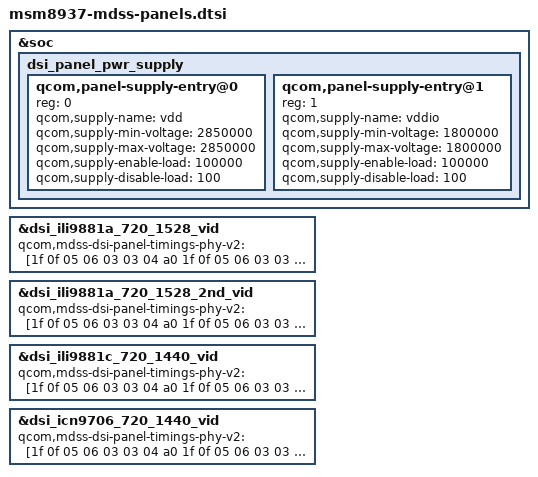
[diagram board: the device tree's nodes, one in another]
/* Copyright (c) 2015-2016, The Linux Foundation. All rights reserved.
 *
 * This program is free software; you can redistribute it and/or modify
 * it under the terms of the GNU General Public License version 2 and
 * only version 2 as published by the Free Software Foundation.
 *
 * This program is distributed in the hope that it will be useful,
 * but WITHOUT ANY WARRANTY; without even the implied warranty of
 * MERCHANTABILITY or FITNESS FOR A PARTICULAR PURPOSE.  See the
 * GNU General Public License for more details.
 */
#include "dsi-panel-icn9706-720-1440p-video.dtsi"
#include "dsi-panel-ili9881c-720-1440p-video.dtsi"
#include "dsi-panel-ili9881a-720-1528p-video.dtsi"
#include "dsi-panel-ili9881a-720-1528p-2nd-video.dtsi"

&soc {
	dsi_panel_pwr_supply: dsi_panel_pwr_supply {
		#address-cells = <1>;
		#size-cells = <0>;

		qcom,panel-supply-entry@0 {
			reg = <0>;
			qcom,supply-name = "vdd";
			qcom,supply-min-voltage = <2850000>;
			qcom,supply-max-voltage = <2850000>;
			qcom,supply-enable-load = <100000>;
			qcom,supply-disable-load = <100>;
		};

		qcom,panel-supply-entry@1 {
			reg = <1>;
			qcom,supply-name = "vddio";
			qcom,supply-min-voltage = <1800000>;
			qcom,supply-max-voltage = <1800000>;
			qcom,supply-enable-load = <100000>;
			qcom,supply-disable-load = <100>;
		};

	};
};
&dsi_ili9881a_720_1528_vid {
	qcom,mdss-dsi-panel-timings-phy-v2 = [1f 0f 05 06 03 03 04 a0
		1f 0f 05 06 03 03 04 a0
		1f 0f 05 06 03 03 04 a0
		1f 0f 05 06 03 03 04 a0
		1f 1c 05 06 03 03 04 a0];
};

&dsi_ili9881a_720_1528_2nd_vid {
	qcom,mdss-dsi-panel-timings-phy-v2 = [1f 0f 05 06 03 03 04 a0
		1f 0f 05 06 03 03 04 a0
		1f 0f 05 06 03 03 04 a0
		1f 0f 05 06 03 03 04 a0
		1f 1c 05 06 03 03 04 a0];
};

&dsi_ili9881c_720_1440_vid {
	qcom,mdss-dsi-panel-timings-phy-v2 = [1f 0f 05 06 03 03 04 a0
		1f 0f 05 06 03 03 04 a0
		1f 0f 05 06 03 03 04 a0
		1f 0f 05 06 03 03 04 a0
		1f 1c 05 06 03 03 04 a0];
};

&dsi_icn9706_720_1440_vid {
	qcom,mdss-dsi-panel-timings-phy-v2 = [1f 0f 05 06 03 03 04 a0
		1f 0f 05 06 03 03 04 a0
		1f 0f 05 06 03 03 04 a0
		1f 0f 05 06 03 03 04 a0
		1f 1c 05 06 03 03 04 a0];
};
